# STM32G081 register map
File version: 1.8
CPU: CM0 r0p1, little endian, MPU, no FPU, 2 interrupt priority bits
Registers are 32-bit, read-write, reset 0x0 unless marked. A register's access mark holds for its fields unless they carry their own. Offsets are from the block's base; [hi:lo] are bit positions; {n}, {i} and the like mark numbered series.

## PWR — Power control
Base 0x40007000
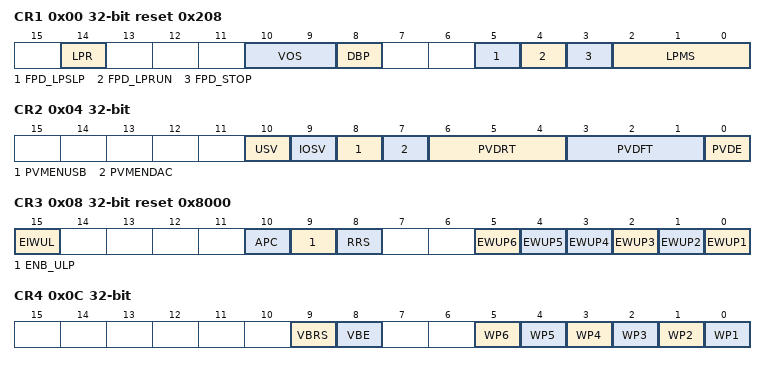
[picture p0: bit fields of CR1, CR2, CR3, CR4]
0x00 CR1 reset 0x208 — Power control register 1
  [14] LPR — Low-power run
  [10:9] VOS — Voltage scaling range selection
  [8] DBP — Disable backup domain write protection
  [5] FPD_LPSLP — Flash memory powered down during Low-power sleep mode
  [4] FPD_LPRUN — Flash memory powered down during Low-power run mode
  [3] FPD_STOP — Flash memory powered down during Stop mode
  [2:0] LPMS — Low-power mode selection
0x04 CR2 — Power control register 2
  [10] USV
  [9] IOSV
  [8] PVMENUSB
  [7] PVMENDAC
  [6:4] PVDRT — Power voltage detector rising threshold selection
  [3:1] PVDFT — Power voltage detector falling threshold selection
  [0] PVDE — Power voltage detector enable
0x08 CR3 reset 0x8000 — Power control register 3
  [15] EIWUL — Enable internal wakeup line
  [10] APC — Apply pull-up and pull-down configuration
  [9] ENB_ULP — Ultra-low-power enable
  [8] RRS — SRAM retention in Standby mode
  [5] EWUP6 — Enable WKUP6 wakeup pin
  [4] EWUP5 — Enable WKUP5 wakeup pin
  [n-1] EWUP{n} (n=1..4) — Enable Wakeup pin WKUP{n}
0x0C CR4 — Power control register 4
  [9] VBRS — VBAT battery charging resistor selection
  [8] VBE — VBAT battery charging enable
  [5] WP6 — WKUP6 wakeup pin polarity
  [n-1] WP{n} (n=1..5) — Wakeup pin WKUP{n} polarity
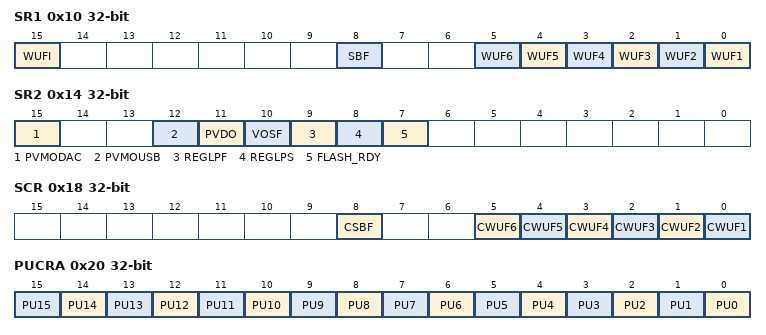
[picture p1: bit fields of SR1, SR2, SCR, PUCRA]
0x10 SR1 ro — Power status register 1
  [15] WUFI — Wakeup flag internal
  [8] SBF — Standby flag
  [n-1] WUF{n} (n=1..6) — Wakeup flag {n}
0x14 SR2 ro — Power status register 2
  [15] PVMODAC — VDDA monitoring output flag
  [12] PVMOUSB — USB supply voltage monitoring output flag
  [11] PVDO — Power voltage detector output
  [10] VOSF — Voltage scaling flag
  [9] REGLPF — Low-power regulator flag
  [8] REGLPS — Low-power regulator started
  [7] FLASH_RDY — Flash ready flag
0x18 SCR wo — Power status clear register
  [8] CSBF — Clear standby flag
  [n-1] CWUF{n} (n=1..6) — Clear wakeup flag {n}
0x20 PUCRA — Power Port A pull-up control register
  [n] PU{n} (n=0..15) — Port A pull-up bit y (y=0..15)
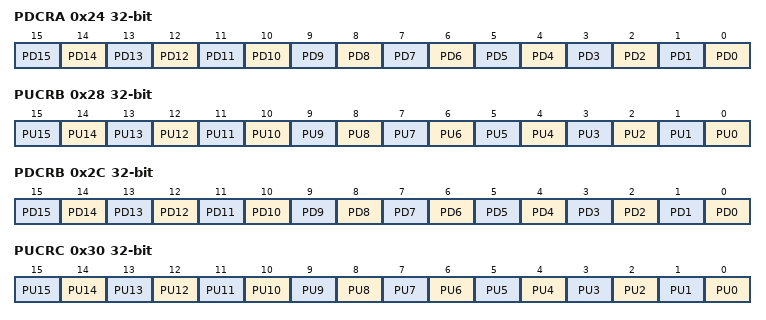
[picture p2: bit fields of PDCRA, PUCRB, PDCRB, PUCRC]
0x24 PDCRA — Power Port A pull-down control register
  [n] PD{n} (n=0..15) — Port A pull-down bit y (y=0..15)
0x28 PUCRB — Power Port B pull-up control register
  [n] PU{n} (n=0..15) — Port B pull-up bit y (y=0..15)
0x2C PDCRB — Power Port B pull-down control register
  [n] PD{n} (n=0..15) — Port B pull-down bit y (y=0..15)
0x30 PUCRC — Power Port C pull-up control register
  [n] PU{n} (n=0..15) — Port C pull-up bit y (y=0..15)
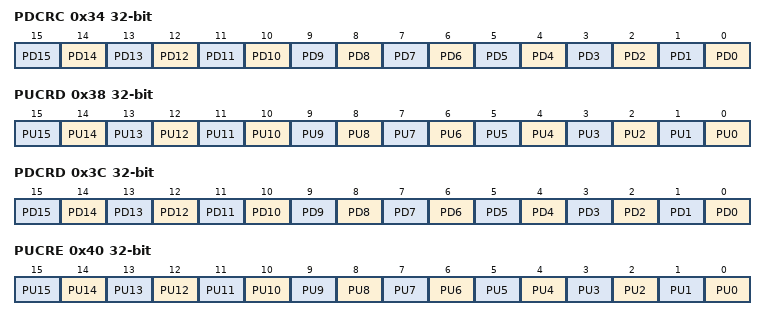
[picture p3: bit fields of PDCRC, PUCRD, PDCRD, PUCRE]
0x34 PDCRC — Power Port C pull-down control register
  [n] PD{n} (n=0..15) — Port C pull-down bit y (y=0..15)
0x38 PUCRD — Power Port D pull-up control register
  [n] PU{n} (n=0..15) — Port D pull-up bit y (y=0..15)
0x3C PDCRD — Power Port D pull-down control register
  [n] PD{n} (n=0..15) — Port D pull-down bit y (y=0..15)
0x40 PUCRE — Power Port E pull-UP control register
  [n] PU{n} (n=0..15) — Port E pull-up bit y (y=0..15)
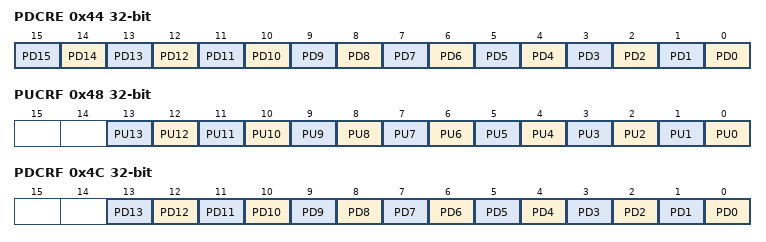
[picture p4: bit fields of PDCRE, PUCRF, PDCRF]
0x44 PDCRE — Power Port E pull-down control register
  [n] PD{n} (n=0..15) — Port E pull-down bit y (y=0..15)
0x48 PUCRF — Power Port F pull-up control register
  [n] PU{n} (n=0..13) — Port F pull-up bit y (y=0..15)
0x4C PDCRF — Power Port F pull-down control register
  [n] PD{n} (n=0..13) — Port F pull-down bit y (y=0..15)

## GPIOA — General-purpose I/Os
Base 0x50000000
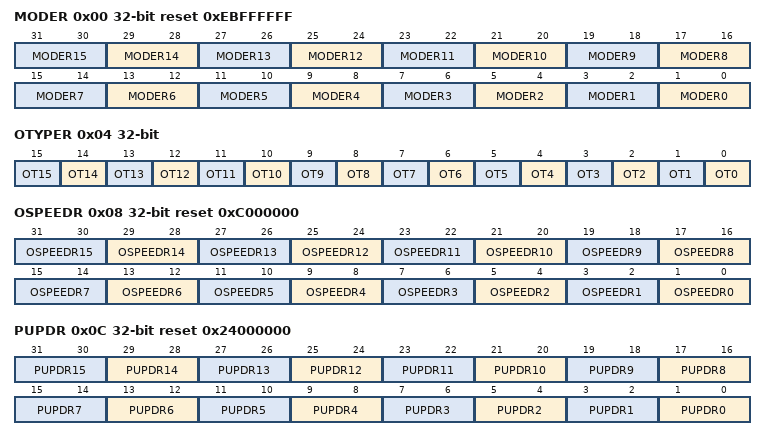
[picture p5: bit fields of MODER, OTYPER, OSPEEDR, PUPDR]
0x00 MODER reset 0xEBFFFFFF — GPIO port mode register
  [2n+1:2n] MODER{n} (n=0..15) — Port x configuration pin {n}
    0=Input mode; 1=Output (General purpose output mode); 2=Alternate function mode; 3=Analog mode
0x04 OTYPER — GPIO port output type register
  [n] OT{n} (n=0..15) — Port x configuration pin {n}
    0=PushPull (Output push-pull (reset state)); 1=OpenDrain (Output open-drain)
0x08 OSPEEDR reset 0xC000000 — GPIO port output speed register
  [2n+1:2n] OSPEEDR{n} (n=0..15) — Port x configuration pin {n}
    0=LowSpeed; 1=MediumSpeed; 2=HighSpeed; 3=VeryHighSpeed
0x0C PUPDR reset 0x24000000 — GPIO port pull-up/pull-down register
  [2n+1:2n] PUPDR{n} (n=0..15) — Port x configuration pin {n}
    0=Floating (No pull-up, pull-down); 1=PullUp; 2=PullDown
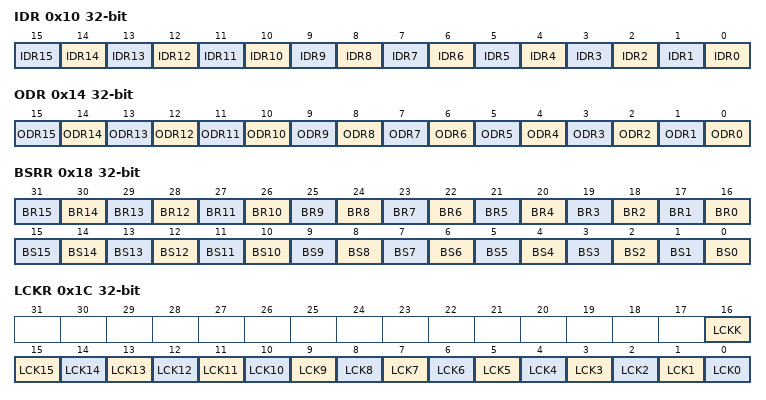
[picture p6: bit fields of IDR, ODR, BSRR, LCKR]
0x10 IDR ro — GPIO port input data register
  [n] IDR{n} (n=0..15) — Port input data pin {n}
    0=Low (Input is logic low); 1=High (Input is logic high)
0x14 ODR — GPIO port output data register
  [n] ODR{n} (n=0..15) — Port output data pin {n}
    0=Low (Set output to logic low); 1=High (Set output to logic high)
0x18 BSRR wo — GPIO port bit set/reset register
  [n+16] BR{n} (n=0..15) — Port x reset pin {n}
    1=Resets the corresponding ODx bit
  [n] BS{n} (n=0..15) — Port x set pin {n}
    1=Set (Sets the corresponding ODx bit)
0x1C LCKR — GPIO port configuration lock register
  [16] LCKK — Port x lock bit y (y= 0..15)
    0=NotActive (Port configuration lock key not active); 1=Active (Port configuration lock key active)
  [n] LCK{n} (n=0..15) — Port x lock pin {n}
    0=Unlocked (Port configuration not locked); 1=Locked (Port configuration locked)
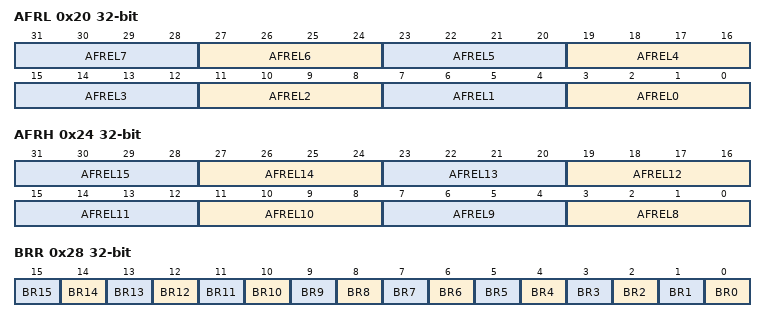
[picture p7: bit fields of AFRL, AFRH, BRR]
0x20 AFRL — GPIO alternate function low register
  [3:0] AFR{x} (x=EL0,EL1,EL2,EL3,EL4,EL5,EL6,EL7; step 4) — Alternate function selection for port x bit y (y = 0..7)
    {v}=AF{v} (v=0..7)
0x24 AFRH — GPIO alternate function high register
  [3:0] AFR{x} (x=EL8,EL9,EL10,EL11,EL12,EL13,EL14,EL15; step 4) — Alternate function selection for port x bit y (y = 8..15)
    {v}=AF{v} (v=0..7)
0x28 BRR wo — port bit reset register
  [n] BR{n} (n=0..15) — Port x reset pin {n}
    0=No action on the corresponding ODx bit; 1=Reset the ODx bit

## GPIOB — General-purpose I/Os
Base 0x50000400
Same registers: GPIOC 0x50000800, GPIOD 0x50000C00, GPIOF 0x50001400
Registers as GPIOA; these are added or differ:
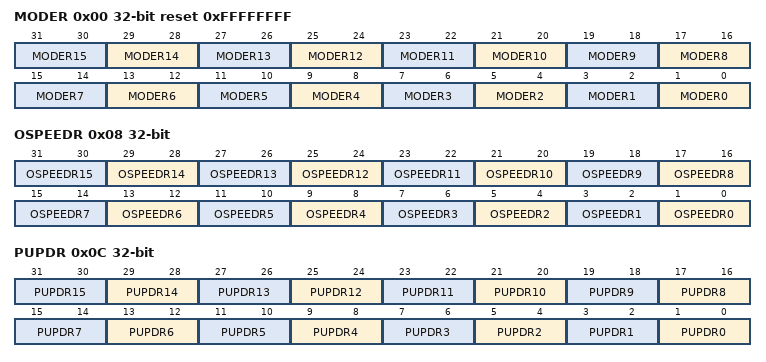
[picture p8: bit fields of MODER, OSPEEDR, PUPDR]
0x00 MODER reset 0xFFFFFFFF — GPIO port mode register
  [2n+1:2n] MODER{n} (n=0..15) — Port x configuration pin {n}
    0=Input mode; 1=Output (General purpose output mode); 2=Alternate function mode; 3=Analog mode
0x08 OSPEEDR — GPIO port output speed register
  [2n+1:2n] OSPEEDR{n} (n=0..15) — Port x configuration pin {n}
    0=LowSpeed; 1=MediumSpeed; 2=HighSpeed; 3=VeryHighSpeed
0x0C PUPDR — GPIO port pull-up/pull-down register
  [2n+1:2n] PUPDR{n} (n=0..15) — Port x configuration pin {n}
    0=Floating (No pull-up, pull-down); 1=PullUp; 2=PullDown
